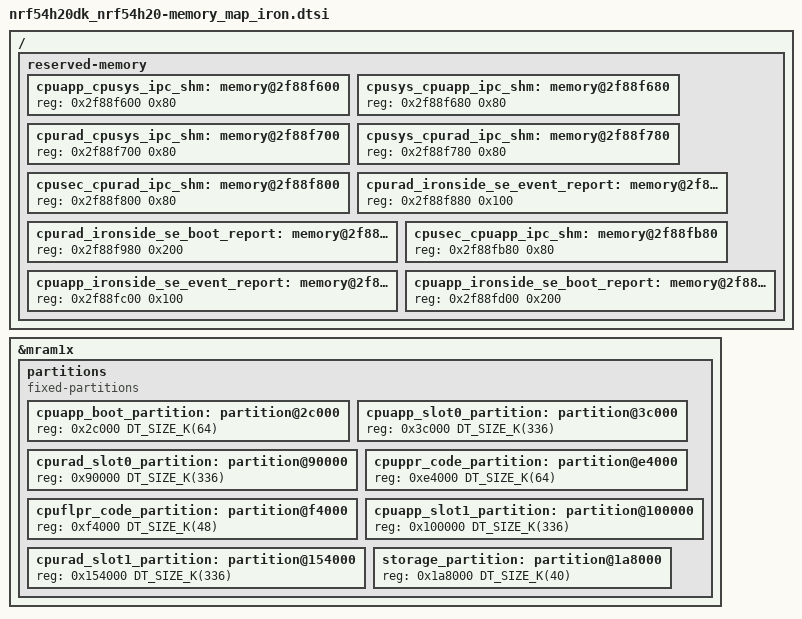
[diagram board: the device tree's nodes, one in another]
/*
 * Copyright (c) 2025 Nordic Semiconductor ASA
 *
 * SPDX-License-Identifier: Apache-2.0
 */

/* This file is to be merged with the original memory_map.dtsi in the future.
 * The following nodes will be replaced:
 */
/delete-node/ &cpuapp_cpusec_ipc_shm;
/delete-node/ &cpuapp_cpusys_ipc_shm;
/delete-node/ &cpurad_cpusec_ipc_shm;
/delete-node/ &cpurad_cpusys_ipc_shm;
/delete-node/ &cpusec_cpuapp_ipc_shm;
/delete-node/ &cpusec_cpurad_ipc_shm;
/delete-node/ &cpusys_cpuapp_ipc_shm;
/delete-node/ &cpusys_cpurad_ipc_shm;
/delete-node/ &cpuapp_rw_partitions;
/delete-node/ &cpuapp_rx_partitions;
/delete-node/ &cpurad_rx_partitions;

/ {
	reserved-memory {
		cpuapp_cpusys_ipc_shm: memory@2f88f600 {
			reg = <0x2f88f600 0x80>;
		};

		cpusys_cpuapp_ipc_shm: memory@2f88f680 {
			reg = <0x2f88f680 0x80>;
		};

		cpurad_cpusys_ipc_shm: memory@2f88f700 {
			reg = <0x2f88f700 0x80>;
		};

		cpusys_cpurad_ipc_shm: memory@2f88f780 {
			reg = <0x2f88f780 0x80>;
		};

		cpusec_cpurad_ipc_shm: memory@2f88f800 {
			reg = <0x2f88f800 0x80>;
		};

		cpurad_ironside_se_event_report: memory@2f88f880 {
			reg = <0x2f88f880 0x100>;
		};

		cpurad_ironside_se_boot_report: memory@2f88f980 {
			reg = <0x2f88f980 0x200>;
		};

		cpusec_cpuapp_ipc_shm: memory@2f88fb80 {
			reg = <0x2f88fb80 0x80>;
		};

		cpuapp_ironside_se_event_report: memory@2f88fc00 {
			reg = <0x2f88fc00 0x100>;
		};

		cpuapp_ironside_se_boot_report: memory@2f88fd00 {
			reg = <0x2f88fd00 0x200>;
		};
	};
};

&mram1x {
	partitions {
		compatible = "fixed-partitions";
		#address-cells = <1>;
		#size-cells = <1>;

		cpuapp_boot_partition: partition@2c000 {
			reg = <0x2c000 DT_SIZE_K(64)>;
		};

		cpuapp_slot0_partition: partition@3c000 {
			reg = <0x3c000 DT_SIZE_K(336)>;
		};

		cpurad_slot0_partition: partition@90000 {
			reg = <0x90000 DT_SIZE_K(336)>;
		};

		cpuppr_code_partition: partition@e4000 {
			reg = <0xe4000 DT_SIZE_K(64)>;
		};

		cpuflpr_code_partition: partition@f4000 {
			reg = <0xf4000 DT_SIZE_K(48)>;
		};

		cpuapp_slot1_partition: partition@100000 {
			reg = <0x100000 DT_SIZE_K(336)>;
		};

		cpurad_slot1_partition: partition@154000 {
			reg = <0x154000 DT_SIZE_K(336)>;
		};

		storage_partition: partition@1a8000 {
			reg = <0x1a8000 DT_SIZE_K(40)>;
		};
	};
};
